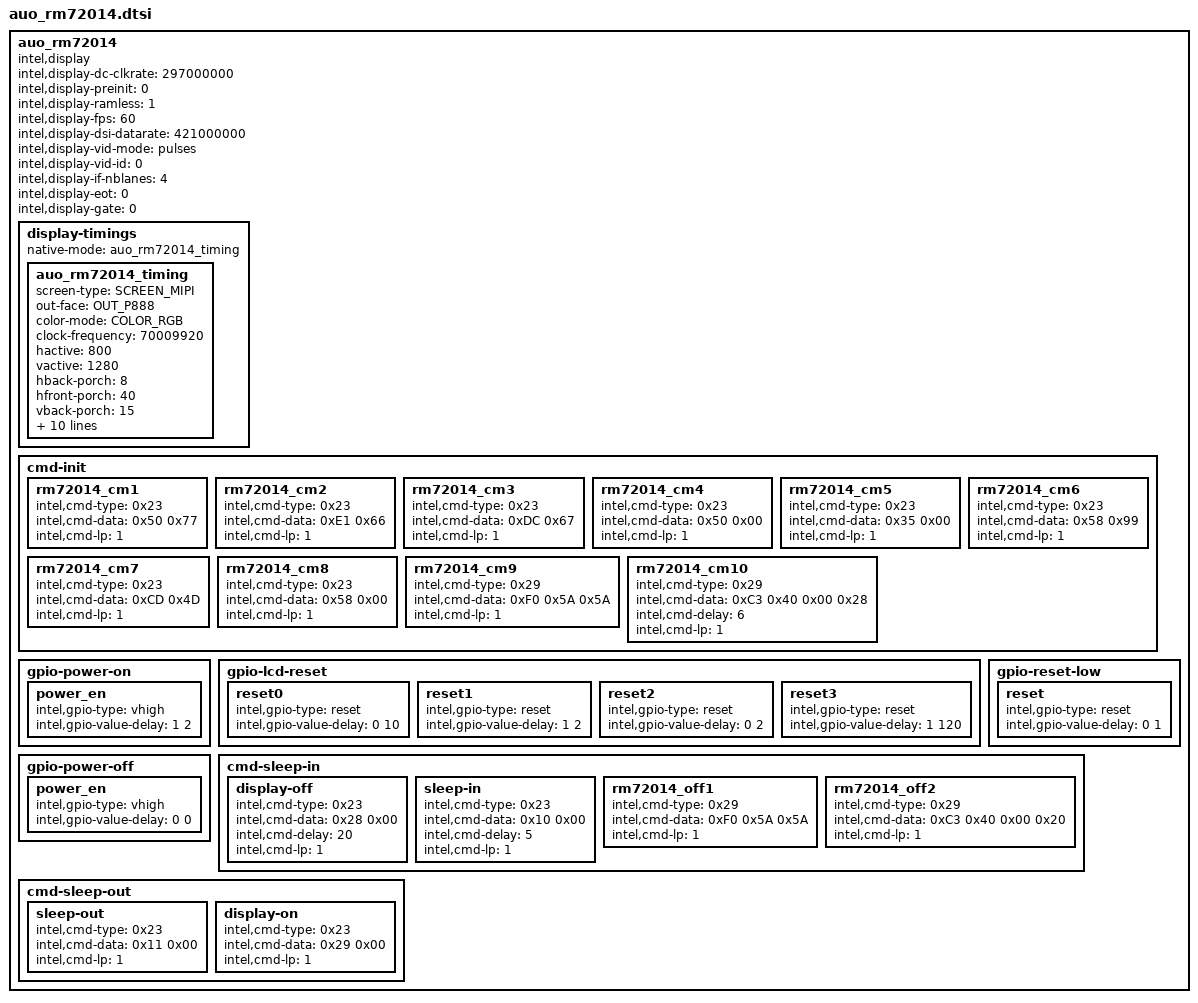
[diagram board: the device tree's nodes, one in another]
/*
 * definition at "include/dt-bindings/sofiafb/sofia_fb.h"
 */

auo_rm72014 {
	compatible = "intel,display";
	intel,display-dc-clkrate = <297000000>;
	intel,display-preinit = <0>;
	intel,display-ramless = <1>;
	intel,display-fps = <60>;
	intel,display-dsi-datarate = <421000000>;
	intel,display-vid-mode = "pulses";
	intel,display-vid-id = <0>;
	intel,display-if-nblanes = <4>;
	intel,display-eot = <0>;
	intel,display-gate = <0>;

	display-timings {
		native-mode = <&auo_rm72014_timing>;
		auo_rm72014_timing: auo_rm72014_timing {
			screen-type = <SCREEN_MIPI>;
			out-face    = <OUT_P888>;
			color-mode = <COLOR_RGB>;
			clock-frequency = <70009920>;
			hactive = <800>;
			vactive = <1280>;
			hback-porch = <8>;
			hfront-porch = <40>;
			vback-porch = <15>;
			vfront-porch = <15>;
			hsync-len = <40>;
			vsync-len = <4>;
			hsync-active = <0>;
			vsync-active = <0>;
			de-active = <0>;
			pixelclk-active = <0>;
			swap-rb = <0>;
			swap-rg = <0>;
			swap-gb = <0>;
		};
	};

	cmd-init {
		rm72014_cm1 {
			intel,cmd-type = <0x23>;
			intel,cmd-data = <0x50 0x77>;
			intel,cmd-lp = <1>;
		};
		rm72014_cm2 {
			intel,cmd-type = <0x23>;
			intel,cmd-data = <0xE1 0x66>;
			intel,cmd-lp = <1>;
		};
		rm72014_cm3 {
			intel,cmd-type = <0x23>;
			intel,cmd-data = <0xDC 0x67>;
			intel,cmd-lp = <1>;
		};
		rm72014_cm4 {
			intel,cmd-type = <0x23>;
			intel,cmd-data = <0x50 0x00>;
			intel,cmd-lp = <1>;
		};
		rm72014_cm5 {
			intel,cmd-type = <0x23>;
			intel,cmd-data = <0x35 0x00>;
			intel,cmd-lp = <1>;
		};
		rm72014_cm6 {
			intel,cmd-type = <0x23>;
			intel,cmd-data = <0x58 0x99>;
			intel,cmd-lp = <1>;
		};
		rm72014_cm7 {
			intel,cmd-type = <0x23>;
			intel,cmd-data = <0xCD 0x4D>;
			intel,cmd-lp = <1>;
		};
		rm72014_cm8 {
			intel,cmd-type = <0x23>;
			intel,cmd-data = <0x58 0x00>;
			intel,cmd-lp = <1>;
		};
		rm72014_cm9 {
			intel,cmd-type = <0x29>;
			intel,cmd-data = <0xF0 0x5A 0x5A>;
			intel,cmd-lp = <1>;
		};
		rm72014_cm10 {
			intel,cmd-type = <0x29>;
			intel,cmd-data = <0xC3 0x40 0x00 0x28>;
			intel,cmd-delay = <6>;
			intel,cmd-lp = <1>;
		};
	};

	gpio-power-on {
		power_en {
			intel,gpio-type = "vhigh";
			intel,gpio-value-delay = <1 2>;
		};
	};

	gpio-lcd-reset {
		reset0 {
			intel,gpio-type = "reset";
			intel,gpio-value-delay = <0 10>;
		};
		reset1 {
			intel,gpio-type = "reset";
			intel,gpio-value-delay = <1 2>;
		};
		reset2 {
			intel,gpio-type = "reset";
			intel,gpio-value-delay = <0 2>;
		};
		reset3 {
			intel,gpio-type = "reset";
			intel,gpio-value-delay = <1 120>;
		};
	};

	gpio-reset-low {
		reset {
			intel,gpio-type = "reset";
			intel,gpio-value-delay = <0 1>;
		};
	};

	gpio-power-off {
		power_en {
			intel,gpio-type = "vhigh";
			intel,gpio-value-delay = <0 0>;
		};
	};

	cmd-sleep-in {
		display-off {
			intel,cmd-type = <0x23>;
			intel,cmd-data = <0x28 0x00>;
			intel,cmd-delay = <20>;
			intel,cmd-lp = <1>;
		};
		sleep-in {
			intel,cmd-type = <0x23>;
			intel,cmd-data = <0x10 0x00>;
			intel,cmd-delay = <5>;
			intel,cmd-lp = <1>;
		};
		rm72014_off1 {
			intel,cmd-type = <0x29>;
			intel,cmd-data = <0xF0 0x5A 0x5A>;
			intel,cmd-lp = <1>;
		};
		rm72014_off2 {
			intel,cmd-type = <0x29>;
			intel,cmd-data = <0xC3 0x40 0x00 0x20>;
			intel,cmd-lp = <1>;
		};
	};

	cmd-sleep-out {
		sleep-out {
			intel,cmd-type = <0x23>;
			intel,cmd-data = <0x11 0x00>;
			intel,cmd-lp = <1>;
		};
		display-on {
			intel,cmd-type = <0x23>;
			intel,cmd-data = <0x29 0x00>;
			intel,cmd-lp = <1>;
		};
	};
};
